AUTOSAR XML (schema 00047)
standard types defined: uint16, uint8
package /DemoApplication/ConstantSpecifications
  constant specification CONST_0c0f918b8f394b8586f853bd5: value-spec=CONST_0c0f918b8f394b8586f853bd5:0
  constant specification CONST_951406b330e947ed9394eb477: value-spec=CONST_951406b330e947ed9394eb477:0
package /DemoApplication/ImplementationDataTypes
  impl type ComM_ModeType: compu {0=NO_COMMUNICATION, 1=SILENT_COMMUNICATION, 2=FULL_COMMUNICATION}, implementation-data-type=uint8
package /DemoApplication/PortInterfaces
  client server interface ComM_UserRequest: is-service=true
    operation RequestComMode: possible-error=[E_MODE_LIMITATION, ComM_UserRequest/E_NOT_OK]
      arg ComMode: type=ComM_ModeType, direction=IN
    error E_MODE_LIMITATION: error-code=2
    error E_NOT_OK: error-code=1
  client server interface DETService: is-service=true
    operation ReportError: possible-error=DETService/E_OK
      arg InstanceId: type=uint8, direction=IN
      arg ApiId: type=uint8, direction=IN
      arg ErrorId: type=uint8, direction=IN
    error E_OK: error-code=0
  sender receiver interface IfAdcVoltage
    data ArgData: type=uint16
  sender receiver interface IfLedCntrl
    data LedData: type=LedType, init-value=false
  sender receiver interface If_Counter
    data CounterValue: type=uint8, init-value=CONST_951406b330e947ed9394eb477:0
  client server interface If_CounterModify
    operation SetCounterAndAdd
      arg newCounterValue: type=uint8, direction=IN
      arg returnSum: type=uint8, direction=OUT
  client server interface If_CounterModify_FD
    operation SetCounterAndAdd_FD
      arg newCounterValue: type=uint8, direction=IN
      arg returnSum: type=uint8, direction=OUT
  sender receiver interface If_Counter_FD
    data CounterValue_FD: type=uint8, init-value=CONST_951406b330e947ed9394eb477:0
  client server interface If_DiscreteValueOutput
    operation SetDiscreteValue
      arg value: type=uint32, direction=IN
  sender receiver interface If_Internal
    data EventMessage: sw-impl-policy=QUEUED, type=uint8
  app type LedType: category=BOOLEAN, compu {0=false, 1=true}
  unit NoUnit
  client server interface NvMService: is-service=true
    operation SetRamBlockStatus: possible-error=NvMService/E_NOT_OK
      arg BlockChanged: type=boolean, direction=IN
    error E_NOT_OK: error-code=1
    error E_OK: error-code=0
  client server interface NvMService0: is-service=true
    operation ReadBlock: fire-and-forget=false
      arg ReadArg: type=uint8, direction=IN, server-argument-impl-policy=USE-ARGUMENT-TYPE
    operation WriteBlock: fire-and-forget=false
      arg WriteArg: type=uint8, direction=IN, server-argument-impl-policy=USE-ARGUMENT-TYPE
    error E_NOT_OK: error-code=1
    error E_OK: error-code=0
package /DemoApplication/SwComponentTypes
  sw addr method LEDCODE: memory-allocation-keyword-policy=ADDR-METHOD-SHORT-NAME
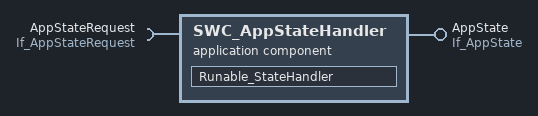
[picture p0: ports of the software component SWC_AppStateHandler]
  application sw component type SWC_AppStateHandler
    provide port AppState: mode-switch-sender-com-spec{mode-group=AppStateMode, queue-length=2}, provided-interface=If_AppState
    require port AppStateRequest: nonqueued-receiver-com-spec{data-element=If_AppStateRequestMode, init-value=EB_INTGR_APP_STARTUP}, required-interface=If_AppStateRequest
    behavior IB_SWC_AppStateHandler: data-type-mapping=AppModeMapping, handle-termination-and-restart=NO-SUPPORT
      data received event AppState: start-on-event=Runable_StateHandler, data=AppStateRequest.If_AppStateRequestMode
      runnable Runable_StateHandler: mode-access-point=AppState.AppStateMode, symbol=App_StateHandler
        data-read-access:
          access DRA_requestMode: accessed-variable=AppStateRequest.If_AppStateRequestMode
        mode switch point MSP_Mode: mode-group=AppState.AppStateMode
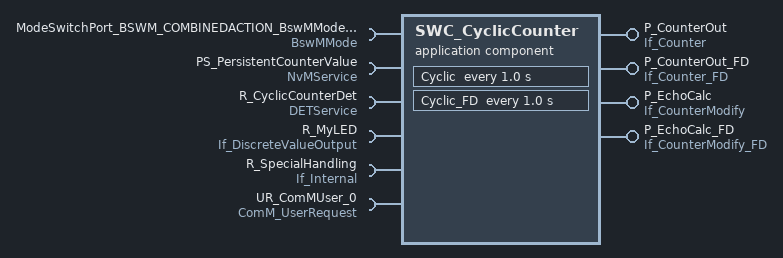
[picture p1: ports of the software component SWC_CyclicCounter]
  application sw component type SWC_CyclicCounter
    require port ModeSwitchPort_BSWM_COMBINEDACTION_BswMMode_PortInterfaces_BswMMode: required-interface=BswMMode
    require port PS_PersistentCounterValue: required-interface=NvMService
    4 x provide port:
      P_CounterOut: nonqueued-sender-com-spec{data-element=CounterValue, init-value=0}, provided-interface=If_Counter
      P_CounterOut_FD: nonqueued-sender-com-spec{data-element=CounterValue_FD, init-value=0}, provided-interface=If_Counter_FD
      P_EchoCalc: server-com-spec{operation=SetCounterAndAdd, queue-length=1}, provided-interface=If_CounterModify
      P_EchoCalc_FD: server-com-spec{operation=SetCounterAndAdd_FD, queue-length=1}, provided-interface=If_CounterModify_FD
    4 x require port:
      R_CyclicCounterDet: required-interface=DETService
      R_MyLED: required-interface=If_DiscreteValueOutput
      R_SpecialHandling: queued-receiver-com-spec{data-element=EventMessage, queue-length=8}, required-interface=If_Internal
      UR_ComMUser_0: required-interface=ComM_UserRequest
    behavior IB_SWC_CyclicCounter: data-type-mapping=BswMModeMapping, handle-termination-and-restart=NO-SUPPORT
      timing event CyclicEvent: start-on-event=Cyclic, period=1.0
        disabled-mode:
          ModeSwitchPort_BSWM_COMBINEDACTION_BswMMode_PortInterfaces_BswMMode.CurrentMode.EB_INTGR_BSWM_GO_OFF_ONE_A
          ModeSwitchPort_BSWM_COMBINEDACTION_BswMMode_PortInterfaces_BswMMode.CurrentMode.EB_INTGR_BSWM_GO_OFF_ONE_B
          ModeSwitchPort_BSWM_COMBINEDACTION_BswMMode_PortInterfaces_BswMMode.CurrentMode.EB_INTGR_BSWM_PRP_SHUTDOWN
          ModeSwitchPort_BSWM_COMBINEDACTION_BswMMode_PortInterfaces_BswMMode.CurrentMode.EB_INTGR_BSWM_STARTUP_TWO_A
          ModeSwitchPort_BSWM_COMBINEDACTION_BswMMode_PortInterfaces_BswMMode.CurrentMode.EB_INTGR_BSWM_STARTUP_TWO_B
          ModeSwitchPort_BSWM_COMBINEDACTION_BswMMode_PortInterfaces_BswMMode.CurrentMode.EB_INTGR_BSWM_WAKEUP_TWO
      timing event CyclicEvent_FD: start-on-event=Cyclic_FD, period=1.0
        disabled-mode:
          ModeSwitchPort_BSWM_COMBINEDACTION_BswMMode_PortInterfaces_BswMMode.CurrentMode.EB_INTGR_BSWM_GO_OFF_ONE_A
          ModeSwitchPort_BSWM_COMBINEDACTION_BswMMode_PortInterfaces_BswMMode.CurrentMode.EB_INTGR_BSWM_GO_OFF_ONE_B
          ModeSwitchPort_BSWM_COMBINEDACTION_BswMMode_PortInterfaces_BswMMode.CurrentMode.EB_INTGR_BSWM_PRP_SHUTDOWN
          ModeSwitchPort_BSWM_COMBINEDACTION_BswMMode_PortInterfaces_BswMMode.CurrentMode.EB_INTGR_BSWM_STARTUP_TWO_A
          ModeSwitchPort_BSWM_COMBINEDACTION_BswMMode_PortInterfaces_BswMMode.CurrentMode.EB_INTGR_BSWM_STARTUP_TWO_B
          ModeSwitchPort_BSWM_COMBINEDACTION_BswMMode_PortInterfaces_BswMMode.CurrentMode.EB_INTGR_BSWM_WAKEUP_TWO
      swc mode switch event ModeSwitchedPrpShutdown: start-on-event=Shutdown, activation=ON-ENTRY, mode=ModeSwitchPort_BSWM_COMBINEDACTION_BswMMode_PortInterfaces_BswMMode.CurrentMode.EB_INTGR_BSWM_PRP_SHUTDOWN
      swc mode switch event ModeSwitchedRunTwo: start-on-event=Init, activation=ON-ENTRY, mode=ModeSwitchPort_BSWM_COMBINEDACTION_BswMMode_PortInterfaces_BswMMode.CurrentMode.EB_INTGR_BSWM_RUN_TWO
      operation invoked event SetCounterOperationInvoked: start-on-event=SetCounter, operation=P_EchoCalc.SetCounterAndAdd
      operation invoked event SetCounterOperationInvoked_FD: start-on-event=SetCounter_FD, operation=P_EchoCalc_FD.SetCounterAndAdd_FD
      explicit-inter-runnable-variables:
        data CurrentCounterValue: type=uint8, init-value=0
        data CurrentCounterValue_FD: type=uint8, init-value=0
      per instance memory PimCounterValue: init-value=99, type=CounterValueType, type-definition=uint8
      per-instance-parameters:
        parameter data prototype PrmCounterValue: type=uint8, init-value=99
      port-api-options:
        enable-take-address=false, indirect-api=false, port=P_EchoCalc
        enable-take-address=false, indirect-api=false, port=SWC_CyclicCounter/P_CounterOut
        enable-take-address=false, indirect-api=false, port=SWC_CyclicCounter/P_CounterOut_FD
      6 x runnable:
        Cyclic: symbol=SWC_CyclicCounter_Cyclic
          data-receive-point-by-arguments:
            access DRP_P_Special_EventMessage: accessed-variable=R_SpecialHandling.EventMessage
          data-send-points:
            access DWA_P_CounterOut_CounterValue: accessed-variable=P_CounterOut.CounterValue
          read-local-variables:
            access CurrentCounterValue3: accessed-variable=CurrentCounterValue
          sync call CS_DETService_ReportError: operation=R_CyclicCounterDet.ReportError, timeout=0.0
          sync call CS_EchoResult_SetCounterAndAdd: operation=R_MyLED.SetDiscreteValue, timeout=0.0
          sync call CS_UR_ComMUser_0_ComM_UserRequest: operation=UR_ComMUser_0.RequestComMode, timeout=0.0
          written-local-variables:
            access CurrentCounterValue4: accessed-variable=CurrentCounterValue
        Cyclic_FD: symbol=SWC_CyclicCounter_Cyclic_FD
          data-send-points:
            access DWA_P_CounterOut_CounterValue: accessed-variable=P_CounterOut_FD.CounterValue_FD
          read-local-variables:
            access CurrentCounterValue3: accessed-variable=CurrentCounterValue_FD
          written-local-variables:
            access CurrentCounterValue4: accessed-variable=CurrentCounterValue_FD
        Init: symbol=SWC_CyclicCounter_Init
          parameter access PA_PersistentCounterValue: accessed-parameter=PrmCounterValue
          sync call CS_UR_ComMUser_0_ComM_UserRequest: operation=UR_ComMUser_0.RequestComMode, timeout=0.0
          written-local-variables:
            access CurrentCounterValue: accessed-variable=CurrentCounterValue
        SetCounter: can-be-invoked-concurrently=true, symbol=SWC_CyclicCounter_SetCounter
          read-local-variables:
            access CurrentCounterValue1: accessed-variable=CurrentCounterValue
          written-local-variables:
            access CurrentCounterValue2: accessed-variable=CurrentCounterValue
        SetCounter_FD: can-be-invoked-concurrently=true, symbol=SWC_CyclicCounter_SetCounter_FD
          read-local-variables:
            access CurrentCounterValue1: accessed-variable=CurrentCounterValue_FD
          written-local-variables:
            access CurrentCounterValue2: accessed-variable=CurrentCounterValue_FD
        Shutdown: symbol=SWC_CyclicCounter_Shutdown
          read-local-variables:
            access CurrentCounterValue3: accessed-variable=CurrentCounterValue
          sync call CS_NvMService_SetRamBlockStatus: operation=PS_PersistentCounterValue.SetRamBlockStatus, timeout=0.0
      swc service dependency ServiceDependency: assigned-ports=role-based-port-assignment={port-prototype=PS_PersistentCounterValue, role=NvMService}
        assigned-datas:
          role=ramMirror, used-pim=PimCounterValue
          role=defaultValue, used-parameter-element=PrmCounterValue
        service-needs:
          nv block needs PersistentCounterValue: calc-ram-block-crc=false, check-static-block-id=false, n-data-sets=1, n-rom-blocks=1, readonly=false, reliability=NO-PROTECTION, resistant-to-changed-sw=false, restore-at-start=true, store-at-shutdown=true, write-only-once=false, write-verification=false, writing-priority=MEDIUM
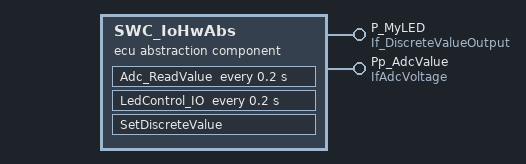
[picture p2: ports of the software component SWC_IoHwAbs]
  ecu abstraction sw component type SWC_IoHwAbs
    provide port P_MyLED: server-com-spec{operation=SetDiscreteValue, queue-length=1}, provided-interface=If_DiscreteValueOutput
    provide port Pp_AdcValue: nonqueued-sender-com-spec{data-element=ArgData, handle-out-of-range=DEFAULT, uses-end-to-end-protection=0, init-value=0}, provided-interface=IfAdcVoltage
    behavior IB_SWC_IoHwAbs: handle-termination-and-restart=NO-SUPPORT, port-api-option{enable-take-address=false, indirect-api=false, port-defined-argument-value{value=0, value-type=uint32}, port=P_MyLED}
      timing event Adc_timingEvent: start-on-event=Adc_ReadValue, offset=0.0, period=0.2
      timing event LedTiming: start-on-event=LedControl_IO, offset=0.0, period=0.2
      operation invoked event SetDiscreteValueOperationInvoked: start-on-event=SetDiscreteValue, operation=P_MyLED.SetDiscreteValue
      runnable Adc_ReadValue
        data-send-points:
          access dsp_ArgData: accessed-variable=Pp_AdcValue.ArgData
      runnable LedControl_IO: can-be-invoked-concurrently=true
      runnable SetDiscreteValue: can-be-invoked-concurrently=true, symbol=SWC_IoHwAbs_SetDiscreteValue
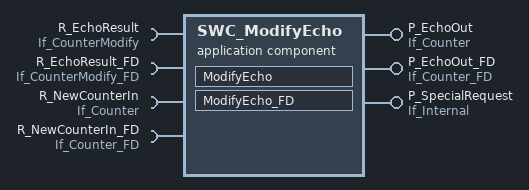
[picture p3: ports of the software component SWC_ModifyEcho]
  application sw component type SWC_ModifyEcho
    provide port P_EchoOut: nonqueued-sender-com-spec{data-element=CounterValue, init-value=0}, provided-interface=If_Counter
    provide port P_EchoOut_FD: nonqueued-sender-com-spec{data-element=CounterValue_FD, init-value=0}, provided-interface=If_Counter_FD
    provide port P_SpecialRequest: provided-interface=If_Internal
    4 x require port:
      R_EchoResult: required-interface=If_CounterModify
      R_EchoResult_FD: required-interface=If_CounterModify_FD
      R_NewCounterIn: nonqueued-receiver-com-spec{data-element=CounterValue, init-value=constant-reference=CONST_0c0f918b8f394b8586f853bd5}, required-interface=If_Counter
      R_NewCounterIn_FD: nonqueued-receiver-com-spec{data-element=CounterValue_FD, init-value=constant-reference=CONST_0c0f918b8f394b8586f853bd5}, required-interface=If_Counter_FD
    behavior IB_SWC_ModifyEcho: handle-termination-and-restart=NO-SUPPORT
      data received event DataReceivedEvent: start-on-event=ModifyEcho, data=R_NewCounterIn.CounterValue
      data received event DataReceivedEvent_FD: start-on-event=ModifyEcho_FD, data=R_NewCounterIn_FD.CounterValue_FD
      port-api-options:
        enable-take-address=false, indirect-api=false, port=R_EchoResult
        enable-take-address=false, indirect-api=false, port=R_NewCounterIn
        enable-take-address=false, indirect-api=false, port=P_EchoOut
        enable-take-address=false, indirect-api=false, port=R_NewCounterIn_FD
        enable-take-address=false, indirect-api=false, port=P_EchoOut_FD
      runnable ModifyEcho: symbol=SWC_ModifyEcho_ModifyEcho
        data-receive-point-by-arguments:
          access DRP_R_NewCounterIn_CounterValue: accessed-variable=R_NewCounterIn.CounterValue
        data-send-points:
          access DSP_P_Special_EventMessage: accessed-variable=P_SpecialRequest.EventMessage
        data-write-access:
          access DWA_P_EchoOut_CounterValue: accessed-variable=P_EchoOut.CounterValue
        sync call CS_EchoResult_SetCounterAndAdd: operation=R_EchoResult.SetCounterAndAdd, timeout=0.0
      runnable ModifyEcho_FD: symbol=SWC_ModifyEcho_ModifyEcho_FD
        data-receive-point-by-arguments:
          access DRP_R_NewCounterIn_CounterValue_FD: accessed-variable=R_NewCounterIn_FD.CounterValue_FD
        data-write-access:
          access DWA_P_EchoOut_CounterValue_FD: accessed-variable=P_EchoOut_FD.CounterValue_FD
        sync call CS_EchoResult_SetCounterAndAdd_FD: operation=R_EchoResult_FD.SetCounterAndAdd_FD, timeout=0.0
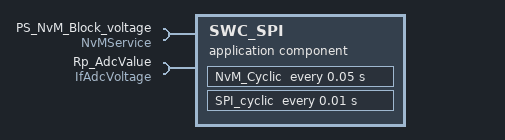
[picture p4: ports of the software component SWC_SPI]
  application sw component type SWC_SPI
    require port PS_NvM_Block_voltage: required-interface=NvMService
    require port Rp_AdcValue: nonqueued-receiver-com-spec=data-element=ArgData, required-interface=IfAdcVoltage
    behavior SWC_SPI_IB_0: handle-termination-and-restart=NO-SUPPORT
      timing event NvM_Cyclic_Event: start-on-event=NvM_Cyclic, offset=0.0, period=0.05
      timing event SPI_cyclic_Tim: start-on-event=SPI_cyclic, offset=0.0, period=0.01
      init event SPI_int
      runnable NvM_Cyclic
        data-receive-point-by-arguments:
          access drparg_ArgData: accessed-variable=Rp_AdcValue.ArgData
        sync call scp_ReadBlock: operation=PS_NvM_Block_voltage.ReadBlock, timeout=0.0
        sync call scp_WriteBlock: operation=PS_NvM_Block_voltage.WriteBlock, timeout=0.0
      runnable SPI_cyclic
      swc service dependency NvmBlockNeedvoltage: assigned-datas=role-based-data-assignment=ramBlock, assigned-ports=role-based-port-assignment={port-prototype=PS_NvM_Block_voltage, role=NvMService}
        service-needs:
          nv block needs NvBlockVoltage: n-data-sets=1, reliability=NO-PROTECTION, resistant-to-changed-sw=false, restore-at-start=true, store-at-shutdown=true, write-only-once=false, writing-frequency=0, writing-priority=MEDIUM
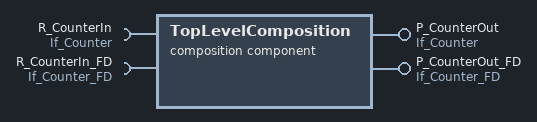
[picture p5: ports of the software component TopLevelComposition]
  composition sw component type TopLevelComposition
    provide port P_CounterOut: provided-interface=If_Counter
    provide port P_CounterOut_FD: provided-interface=If_Counter_FD
    require port R_CounterIn: required-interface=If_Counter
    require port R_CounterIn_FD: required-interface=If_Counter_FD
    5 x component:
      SWC_AppStateHandler: type=SWC_AppStateHandler
      SWC_CyclicCounter: type=SWC_CyclicCounter
      SWC_IoHwAbs: type=SWC_IoHwAbs
      SWC_ModifyEcho: type=SWC_ModifyEcho
      SWC_SPI: type=SWC_SPI
    delegate SWC_ModifyEcho.P_EchoOut_FD <-> outer port TopLevelComposition/P_CounterOut_FD
    delegate SWC_ModifyEcho.R_NewCounterIn_FD <-> outer port R_CounterIn_FD
    connect SWC_CyclicCounter.P_EchoCalc -> SWC_ModifyEcho.R_EchoResult
    delegate SWC_ModifyEcho.P_EchoOut <-> outer port TopLevelComposition/P_CounterOut
    connect SWC_ModifyEcho.P_SpecialRequest -> SWC_CyclicCounter.R_SpecialHandling
    connect SWC_IoHwAbs.P_MyLED -> SWC_CyclicCounter.R_MyLED
    delegate SWC_CyclicCounter.P_CounterOut <-> outer port TopLevelComposition/P_CounterOut
    delegate SWC_ModifyEcho.R_NewCounterIn <-> outer port R_CounterIn
  base type Uint8_user: category=FIXED_LENGTH, base-type-size=8, base-type-encoding=NONE
package /DemoApplication/SwcImplementations
  5 x swc implementation, all with programming-language=C, sw-version=1.0.0:
    Impl_SWC_AppStateHandler: vendor-id=1, behavior=IB_SWC_AppStateHandler
      code-descriptors:
        code SRC: artifact-descriptors=autosar-engineering-object={short-label=EngObject, category=SWSRC}
      resource consumption Resources
        memory section RTE_START_SEC_APPL_CODE: sw-addrmethod=CODE, symbol=CODE
    Impl_SWC_CyclicCounter: vendor-id=1, behavior=IB_SWC_CyclicCounter
      code-descriptors:
        code SRC: artifact-descriptors=autosar-engineering-object={short-label=EngObject, category=SWSRC}
      resource consumption Resources
        memory section RTE_START_SEC_APPL_CODE: sw-addrmethod=CODE, symbol=CODE
    Impl_SWC_IoHwAbs: vendor-id=1, behavior=IB_SWC_IoHwAbs
      code-descriptors:
        code SRC: artifact-descriptors=autosar-engineering-object={short-label=EngObject, category=SWSRC}
      resource consumption Resources
        memory section RTE_START_SEC_APPL_CODE: sw-addrmethod=CODE, symbol=CODE
        memory section RTE_START_SEC_VAR_UNSPECIFIED: sw-addrmethod=VAR, symbol=VAR
    Impl_SWC_ModifyEcho: vendor-id=1, behavior=IB_SWC_ModifyEcho
      code-descriptors:
        code SRC: artifact-descriptors=autosar-engineering-object={short-label=EngObject, category=SWSRC}
      resource consumption Resources
        memory section RTE_START_SEC_APPL_CODE: sw-addrmethod=CODE, symbol=CODE
    Impl_SWC_SPI: vendor-id=0, behavior=SWC_SPI_IB_0
      code-descriptors:
        code SRC: artifact-descriptors=autosar-engineering-object={short-label=EngObject, category=SWSRC}
      resource consumption Resources
        memory section RTE_START_SEC_APPL_CODE: sw-addrmethod=CODE, symbol=CODE
  sw addr method SPICODE: memory-allocation-keyword-policy=ADDR-METHOD-SHORT-NAME
